# CBASS0_ISC register map
Vendor: Texas Instruments
Peripheral module from a debugger description file (folder am62x).
Registers are 32-bit, read-write, reset 0x0 unless marked. A register's access mark holds for its fields unless they carry their own. Offsets are as the file gives them; lines under a group give offsets from that group; [hi:lo] are bit positions; {n}, {i} and the like mark numbered series; 'fields as' and 'values as' point back to an identical list; <NAME> marks a mode.

## CBASS0_ISC
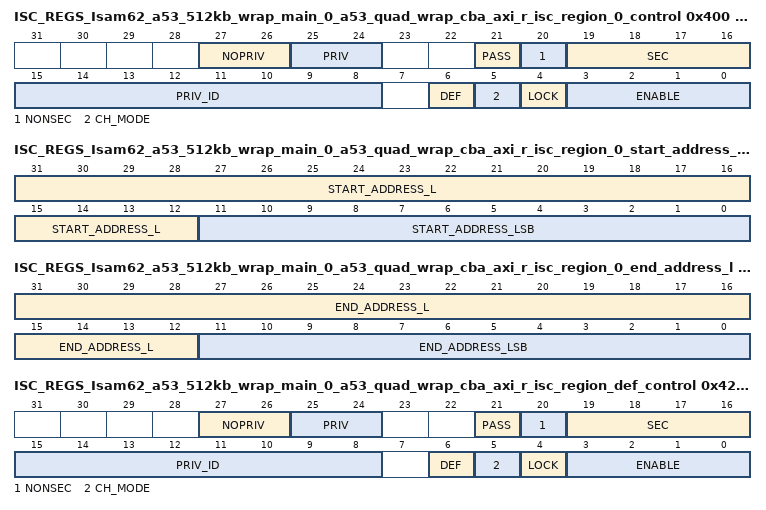
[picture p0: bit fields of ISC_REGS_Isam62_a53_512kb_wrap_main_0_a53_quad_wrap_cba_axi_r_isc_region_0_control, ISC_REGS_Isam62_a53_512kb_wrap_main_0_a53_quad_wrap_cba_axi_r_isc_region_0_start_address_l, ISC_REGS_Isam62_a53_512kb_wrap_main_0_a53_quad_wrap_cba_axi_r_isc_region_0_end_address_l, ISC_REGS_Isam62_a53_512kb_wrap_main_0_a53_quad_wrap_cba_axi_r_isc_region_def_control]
0x400 ISC_REGS_Isam62_a53_512kb_wrap_main_0_a53_quad_wrap_cba_axi_r_isc_region_0_control access not given reset 0x400 — The ISC Region 0 Control Register defines the control fields for the master Isam62_a53_512kb_wrap_main_0.a53_quad_wrap_cba_axi_r region 0 ISC.
  [27:26] NOPRIV rw — Clear output priv attribute. If each bit is set then the outgoing priv bit is cleared.
  [25:24] PRIV rw — Set outgoing priv attribute. If each bit is set then the outgoing priv bit is set.
  [21] PASS rw — No privID replacement, pass through value.
  [20] NONSEC rw — Make outgoing non-secure.
  [19:16] SEC rw — Make outgoing secure. A value of 0xA enables, others disable.
  [15:8] PRIV_ID rw
  [6] DEF ro — Default region indication. The default region is used when all other regions do not match.
  [5] CH_MODE rw — Enable channel mode to match region to a chanid value. Otherwise use address mode to match region to an address range.
  [4] LOCK — Lock region. Once set the region values cannot be modified. (access R/W1TS)
  [3:0] ENABLE rw — Enable region. A value of 0xA enables, others disable.
0x410 ISC_REGS_Isam62_a53_512kb_wrap_main_0_a53_quad_wrap_cba_axi_r_isc_region_0_start_address_l — The ISC Region 0 Start Address Low Register defines the start address bits 31 to 0 for the master Isam62_a53_512kb_wrap_main_0.a53_quad_wrap_cba_axi_r region 0 ISC.
  [31:12] START_ADDRESS_L — Start address bits 31 to 12.
  [11:0] START_ADDRESS_LSB — Start address bits 11 to 0 must be 0 as address must be 4KB aligned in address mode. Can also be channel number in channel mode.
0x414 ISC_REGS_Isam62_a53_512kb_wrap_main_0_a53_quad_wrap_cba_axi_r_isc_region_0_start_address_h — The ISC Region 0 Start Address High Register defines the start address bits 47 to 32 for the master Isam62_a53_512kb_wrap_main_0.a53_quad_wrap_cba_axi_r region 0 ISC.
  [15:0] START_ADDRESS_H — Start address bits 47 to 32.
0x418 ISC_REGS_Isam62_a53_512kb_wrap_main_0_a53_quad_wrap_cba_axi_r_isc_region_0_end_address_l access per field reset 0xFFF — The ISC Region 0 End Address Low Register defines the end included address bits 31 to 0 for the master Isam62_a53_512kb_wrap_main_0.a53_quad_wrap_cba_axi_r region 0 ISC.
  [31:12] END_ADDRESS_L rw — End address bits 31 to 12 to include in the match.
  [11:0] END_ADDRESS_LSB ro — End address bits 11 to 0 are forced to Fs as address must be 4KB aligned.
0x41C ISC_REGS_Isam62_a53_512kb_wrap_main_0_a53_quad_wrap_cba_axi_r_isc_region_0_end_address_h — The ISC Region 0 End Address High Register defines the end address bits 47 to 32 for the master Isam62_a53_512kb_wrap_main_0.a53_quad_wrap_cba_axi_r region 0 ISC.
  [15:0] END_ADDRESS_H — End address bits 47 to 32.
0x420 ISC_REGS_Isam62_a53_512kb_wrap_main_0_a53_quad_wrap_cba_axi_r_isc_region_def_control access not given reset 0x44A — The ISC Default Region Control Register defines the control fields for the master Isam62_a53_512kb_wrap_main_0.a53_quad_wrap_cba_axi_r region 1 ISC.
  [27:26] NOPRIV rw — Clear output priv attribute. If each bit is set then the outgoing priv bit is cleared, else the bit is unchanged. Do not set both priv and nopriv for the same bit.
  [25:24] PRIV rw — Set outgoing priv attribute. If each bit is set then the outgoing priv bit is set, else the bit is unchanged. Do not set both priv and nopriv for the same bit.
  [21] PASS rw — No privID replacement. A value of 1 will pass through privid value. A value of 0 will replace privid with priv_id field value.
  [20] NONSEC rw — Make outgoing non-secure. A value of 1 forces secure clear, others do nothing. Do not set both sec and nonsec.
  [19:16] SEC rw — Make outgoing secure. A value of 0xA forces secure set, others do nothing. Do not set both sec and nonsec.
  [15:8] PRIV_ID rw — Priv ID value to use if pass is 0.
  [6] DEF ro — Default region indication. The default region is used when all other regions do not match.
  [5] CH_MODE ro — Enable channel mode to match region to a chanid value. Otherwise use address mode to match region to an address range.
  [4] LOCK — Lock region. Once set, the region values cannot be modified. (access R/W1TS)
  [3:0] ENABLE ro — Enable region. A value of 0xA enables, others disable.
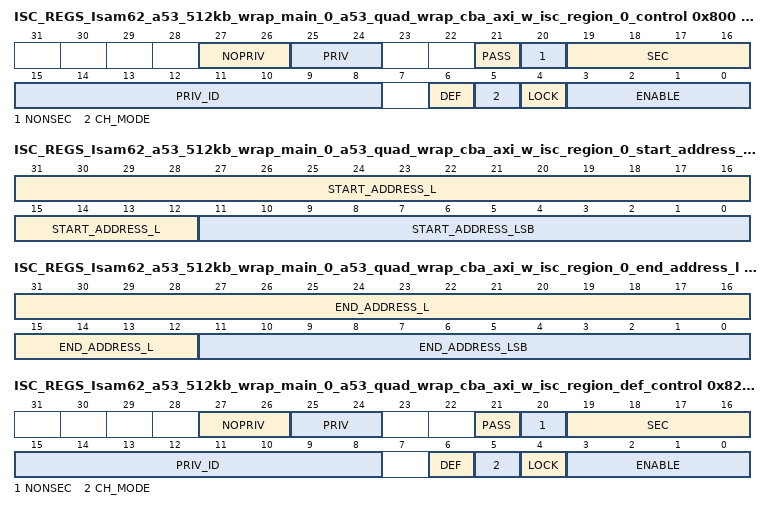
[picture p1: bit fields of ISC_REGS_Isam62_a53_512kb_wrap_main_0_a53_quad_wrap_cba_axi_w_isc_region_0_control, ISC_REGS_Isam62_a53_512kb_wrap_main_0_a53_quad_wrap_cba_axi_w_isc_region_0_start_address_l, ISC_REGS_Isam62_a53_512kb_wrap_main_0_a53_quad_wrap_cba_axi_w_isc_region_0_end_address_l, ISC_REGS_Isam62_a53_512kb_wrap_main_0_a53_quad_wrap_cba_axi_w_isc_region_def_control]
0x800 ISC_REGS_Isam62_a53_512kb_wrap_main_0_a53_quad_wrap_cba_axi_w_isc_region_0_control access not given reset 0x400 — The ISC Region 0 Control Register defines the control fields for the master Isam62_a53_512kb_wrap_main_0.a53_quad_wrap_cba_axi_w region 0 ISC.
  fields as ISC_REGS_Isam62_a53_512kb_wrap_main_0_a53_quad_wrap_cba_axi_r_isc_region_0_control
0x810 ISC_REGS_Isam62_a53_512kb_wrap_main_0_a53_quad_wrap_cba_axi_w_isc_region_0_start_address_l — The ISC Region 0 Start Address Low Register defines the start address bits 31 to 0 for the master Isam62_a53_512kb_wrap_main_0.a53_quad_wrap_cba_axi_w region 0 ISC.
  fields as ISC_REGS_Isam62_a53_512kb_wrap_main_0_a53_quad_wrap_cba_axi_r_isc_region_0_start_address_l
0x814 ISC_REGS_Isam62_a53_512kb_wrap_main_0_a53_quad_wrap_cba_axi_w_isc_region_0_start_address_h — The ISC Region 0 Start Address High Register defines the start address bits 47 to 32 for the master Isam62_a53_512kb_wrap_main_0.a53_quad_wrap_cba_axi_w region 0 ISC.
  [15:0] START_ADDRESS_H — Start address bits 47 to 32.
0x818 ISC_REGS_Isam62_a53_512kb_wrap_main_0_a53_quad_wrap_cba_axi_w_isc_region_0_end_address_l access per field reset 0xFFF — The ISC Region 0 End Address Low Register defines the end included address bits 31 to 0 for the master Isam62_a53_512kb_wrap_main_0.a53_quad_wrap_cba_axi_w region 0 ISC.
  fields as ISC_REGS_Isam62_a53_512kb_wrap_main_0_a53_quad_wrap_cba_axi_r_isc_region_0_end_address_l
0x81C ISC_REGS_Isam62_a53_512kb_wrap_main_0_a53_quad_wrap_cba_axi_w_isc_region_0_end_address_h — The ISC Region 0 End Address High Register defines the end address bits 47 to 32 for the master Isam62_a53_512kb_wrap_main_0.a53_quad_wrap_cba_axi_w region 0 ISC.
  [15:0] END_ADDRESS_H — End address bits 47 to 32.
0x820 ISC_REGS_Isam62_a53_512kb_wrap_main_0_a53_quad_wrap_cba_axi_w_isc_region_def_control access not given reset 0x44A — The ISC Default Region Control Register defines the control fields for the master Isam62_a53_512kb_wrap_main_0.a53_quad_wrap_cba_axi_w region 1 ISC.
  fields as ISC_REGS_Isam62_a53_512kb_wrap_main_0_a53_quad_wrap_cba_axi_r_isc_region_def_control
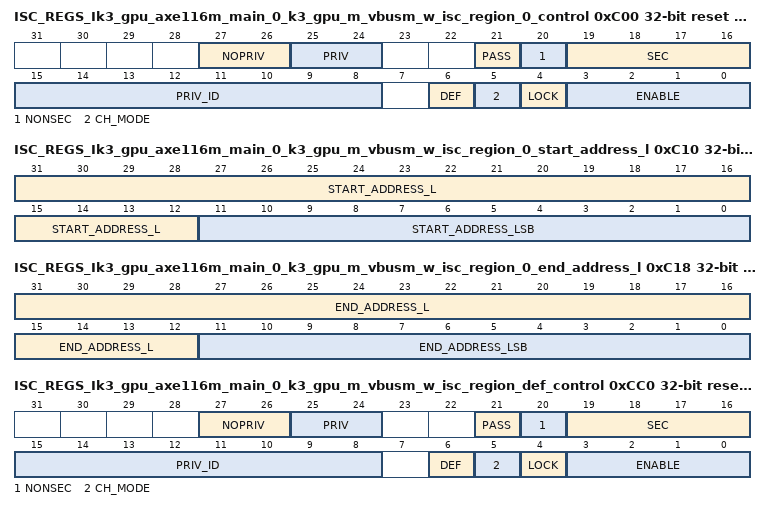
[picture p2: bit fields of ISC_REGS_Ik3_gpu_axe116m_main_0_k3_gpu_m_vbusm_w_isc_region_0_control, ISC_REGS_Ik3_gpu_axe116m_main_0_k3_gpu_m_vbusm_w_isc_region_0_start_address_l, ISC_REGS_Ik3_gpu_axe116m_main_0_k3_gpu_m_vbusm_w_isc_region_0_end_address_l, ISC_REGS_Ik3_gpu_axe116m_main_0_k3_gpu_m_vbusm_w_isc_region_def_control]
{0xC00+0x20*i} ISC_REGS_Ik3_gpu_axe116m_main_0_k3_gpu_m_vbusm_w_isc_region_{i}_control access not given reset 0xBB00 (i=0..5) — The ISC Region {i} Control Register defines the control fields for the master Ik3_gpu_axe116m_main_0.k3_gpu_m_vbusm_w region {i} ISC.
  fields as ISC_REGS_Isam62_a53_512kb_wrap_main_0_a53_quad_wrap_cba_axi_r_isc_region_0_control
{0xC10+0x20*i} ISC_REGS_Ik3_gpu_axe116m_main_0_k3_gpu_m_vbusm_w_isc_region_{i}_start_address_l (i=0..5) — The ISC Region {i} Start Address Low Register defines the start address bits 31 to 0 for the master Ik3_gpu_axe116m_main_0.k3_gpu_m_vbusm_w region {i} ISC.
  fields as ISC_REGS_Isam62_a53_512kb_wrap_main_0_a53_quad_wrap_cba_axi_r_isc_region_0_start_address_l
{0xC14+0x20*i} ISC_REGS_Ik3_gpu_axe116m_main_0_k3_gpu_m_vbusm_w_isc_region_{i}_start_address_h (i=0..5) — The ISC Region {i} Start Address High Register defines the start address bits 47 to 32 for the master Ik3_gpu_axe116m_main_0.k3_gpu_m_vbusm_w region {i} ISC.
  [15:0] START_ADDRESS_H — Start address bits 47 to 32.
{0xC18+0x20*i} ISC_REGS_Ik3_gpu_axe116m_main_0_k3_gpu_m_vbusm_w_isc_region_{i}_end_address_l access per field reset 0xFFF (i=0..5) — The ISC Region {i} End Address Low Register defines the end included address bits 31 to 0 for the master Ik3_gpu_axe116m_main_0.k3_gpu_m_vbusm_w region {i} ISC.
  fields as ISC_REGS_Isam62_a53_512kb_wrap_main_0_a53_quad_wrap_cba_axi_r_isc_region_0_end_address_l
{0xC1C+0x20*i} ISC_REGS_Ik3_gpu_axe116m_main_0_k3_gpu_m_vbusm_w_isc_region_{i}_end_address_h (i=0..5) — The ISC Region {i} End Address High Register defines the end address bits 47 to 32 for the master Ik3_gpu_axe116m_main_0.k3_gpu_m_vbusm_w region {i} ISC.
  [15:0] END_ADDRESS_H — End address bits 47 to 32.
0xCC0 ISC_REGS_Ik3_gpu_axe116m_main_0_k3_gpu_m_vbusm_w_isc_region_def_control access not given reset 0xBB4A — The ISC Default Region Control Register defines the control fields for the master Ik3_gpu_axe116m_main_0.k3_gpu_m_vbusm_w region 6 ISC.
  fields as ISC_REGS_Isam62_a53_512kb_wrap_main_0_a53_quad_wrap_cba_axi_r_isc_region_def_control
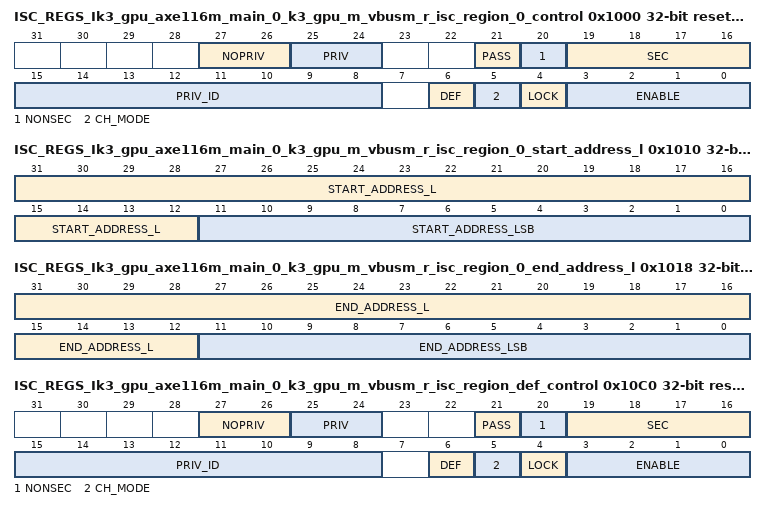
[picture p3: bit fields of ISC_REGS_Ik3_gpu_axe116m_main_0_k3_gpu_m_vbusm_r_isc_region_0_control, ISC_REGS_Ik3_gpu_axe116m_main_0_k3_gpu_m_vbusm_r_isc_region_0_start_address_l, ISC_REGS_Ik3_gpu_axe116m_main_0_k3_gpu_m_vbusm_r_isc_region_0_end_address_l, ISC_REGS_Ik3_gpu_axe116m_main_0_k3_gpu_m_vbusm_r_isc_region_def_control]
{0x1000+0x20*i} ISC_REGS_Ik3_gpu_axe116m_main_0_k3_gpu_m_vbusm_r_isc_region_{i}_control access not given reset 0xBB00 (i=0..5) — The ISC Region {i} Control Register defines the control fields for the master Ik3_gpu_axe116m_main_0.k3_gpu_m_vbusm_r region {i} ISC.
  fields as ISC_REGS_Isam62_a53_512kb_wrap_main_0_a53_quad_wrap_cba_axi_r_isc_region_0_control
{0x1010+0x20*i} ISC_REGS_Ik3_gpu_axe116m_main_0_k3_gpu_m_vbusm_r_isc_region_{i}_start_address_l (i=0..5) — The ISC Region {i} Start Address Low Register defines the start address bits 31 to 0 for the master Ik3_gpu_axe116m_main_0.k3_gpu_m_vbusm_r region {i} ISC.
  fields as ISC_REGS_Isam62_a53_512kb_wrap_main_0_a53_quad_wrap_cba_axi_r_isc_region_0_start_address_l
{0x1014+0x20*i} ISC_REGS_Ik3_gpu_axe116m_main_0_k3_gpu_m_vbusm_r_isc_region_{i}_start_address_h (i=0..5) — The ISC Region {i} Start Address High Register defines the start address bits 47 to 32 for the master Ik3_gpu_axe116m_main_0.k3_gpu_m_vbusm_r region {i} ISC.
  [15:0] START_ADDRESS_H — Start address bits 47 to 32.
{0x1018+0x20*i} ISC_REGS_Ik3_gpu_axe116m_main_0_k3_gpu_m_vbusm_r_isc_region_{i}_end_address_l access per field reset 0xFFF (i=0..5) — The ISC Region {i} End Address Low Register defines the end included address bits 31 to 0 for the master Ik3_gpu_axe116m_main_0.k3_gpu_m_vbusm_r region {i} ISC.
  fields as ISC_REGS_Isam62_a53_512kb_wrap_main_0_a53_quad_wrap_cba_axi_r_isc_region_0_end_address_l
{0x101C+0x20*i} ISC_REGS_Ik3_gpu_axe116m_main_0_k3_gpu_m_vbusm_r_isc_region_{i}_end_address_h (i=0..5) — The ISC Region {i} End Address High Register defines the end address bits 47 to 32 for the master Ik3_gpu_axe116m_main_0.k3_gpu_m_vbusm_r region {i} ISC.
  [15:0] END_ADDRESS_H — End address bits 47 to 32.
0x10C0 ISC_REGS_Ik3_gpu_axe116m_main_0_k3_gpu_m_vbusm_r_isc_region_def_control access not given reset 0xBB4A — The ISC Default Region Control Register defines the control fields for the master Ik3_gpu_axe116m_main_0.k3_gpu_m_vbusm_r region 6 ISC.
  fields as ISC_REGS_Isam62_a53_512kb_wrap_main_0_a53_quad_wrap_cba_axi_r_isc_region_def_control
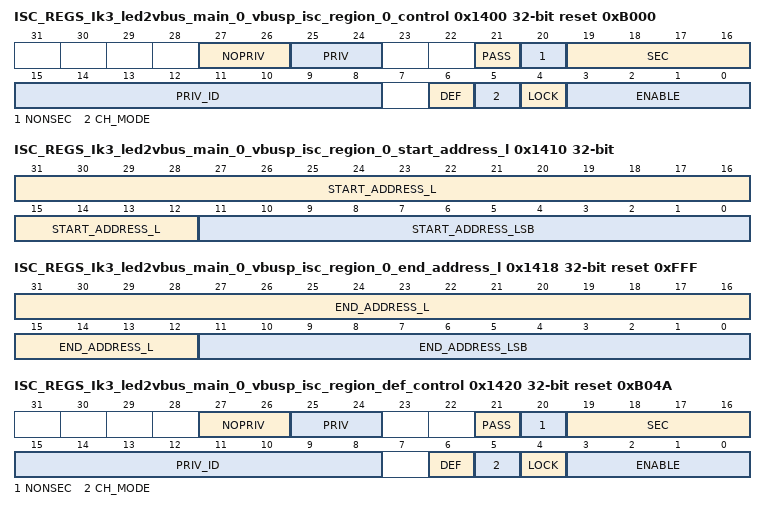
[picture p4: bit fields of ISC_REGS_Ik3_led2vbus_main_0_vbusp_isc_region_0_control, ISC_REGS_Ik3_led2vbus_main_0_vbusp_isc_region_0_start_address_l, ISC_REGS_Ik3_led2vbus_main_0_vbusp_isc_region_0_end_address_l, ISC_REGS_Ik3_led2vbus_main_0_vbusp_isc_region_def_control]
0x1400 ISC_REGS_Ik3_led2vbus_main_0_vbusp_isc_region_0_control access not given reset 0xB000 — The ISC Region 0 Control Register defines the control fields for the master Ik3_led2vbus_main_0.vbusp region 0 ISC.
  fields as ISC_REGS_Isam62_a53_512kb_wrap_main_0_a53_quad_wrap_cba_axi_r_isc_region_0_control
0x1410 ISC_REGS_Ik3_led2vbus_main_0_vbusp_isc_region_0_start_address_l — The ISC Region 0 Start Address Low Register defines the start address bits 31 to 0 for the master Ik3_led2vbus_main_0.vbusp region 0 ISC.
  fields as ISC_REGS_Isam62_a53_512kb_wrap_main_0_a53_quad_wrap_cba_axi_r_isc_region_0_start_address_l
0x1414 ISC_REGS_Ik3_led2vbus_main_0_vbusp_isc_region_0_start_address_h — The ISC Region 0 Start Address High Register defines the start address bits 47 to 32 for the master Ik3_led2vbus_main_0.vbusp region 0 ISC.
  [15:0] START_ADDRESS_H — Start address bits 47 to 32.
0x1418 ISC_REGS_Ik3_led2vbus_main_0_vbusp_isc_region_0_end_address_l access per field reset 0xFFF — The ISC Region 0 End Address Low Register defines the end included address bits 31 to 0 for the master Ik3_led2vbus_main_0.vbusp region 0 ISC.
  fields as ISC_REGS_Isam62_a53_512kb_wrap_main_0_a53_quad_wrap_cba_axi_r_isc_region_0_end_address_l
0x141C ISC_REGS_Ik3_led2vbus_main_0_vbusp_isc_region_0_end_address_h — The ISC Region 0 End Address High Register defines the end address bits 47 to 32 for the master Ik3_led2vbus_main_0.vbusp region 0 ISC.
  [15:0] END_ADDRESS_H — End address bits 47 to 32.
0x1420 ISC_REGS_Ik3_led2vbus_main_0_vbusp_isc_region_def_control access not given reset 0xB04A — The ISC Default Region Control Register defines the control fields for the master Ik3_led2vbus_main_0.vbusp region 1 ISC.
  fields as ISC_REGS_Isam62_a53_512kb_wrap_main_0_a53_quad_wrap_cba_axi_r_isc_region_def_control
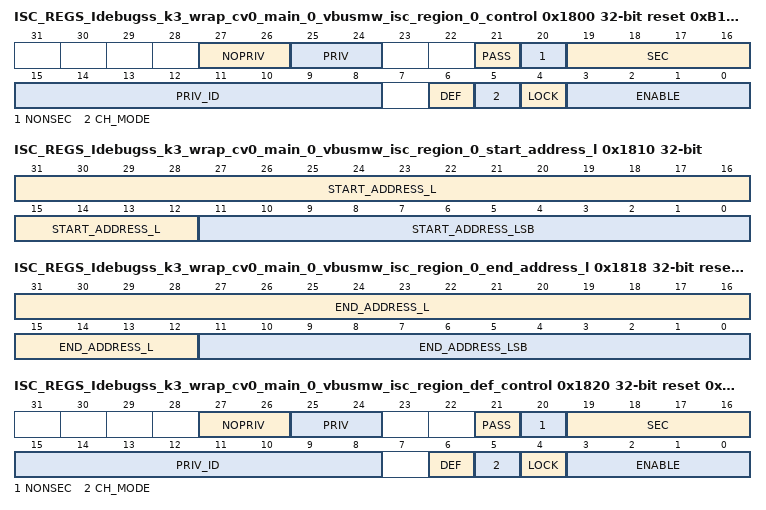
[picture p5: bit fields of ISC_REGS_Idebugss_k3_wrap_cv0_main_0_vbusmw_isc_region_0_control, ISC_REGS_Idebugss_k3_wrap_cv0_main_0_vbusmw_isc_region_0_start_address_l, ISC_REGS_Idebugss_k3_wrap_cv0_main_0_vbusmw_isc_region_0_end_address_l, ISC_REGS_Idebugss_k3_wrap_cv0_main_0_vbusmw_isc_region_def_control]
0x1800 ISC_REGS_Idebugss_k3_wrap_cv0_main_0_vbusmw_isc_region_0_control access not given reset 0xB100 — The ISC Region 0 Control Register defines the control fields for the master Idebugss_k3_wrap_cv0_main_0.vbusmw region 0 ISC.
  fields as ISC_REGS_Isam62_a53_512kb_wrap_main_0_a53_quad_wrap_cba_axi_r_isc_region_0_control
0x1810 ISC_REGS_Idebugss_k3_wrap_cv0_main_0_vbusmw_isc_region_0_start_address_l — The ISC Region 0 Start Address Low Register defines the start address bits 31 to 0 for the master Idebugss_k3_wrap_cv0_main_0.vbusmw region 0 ISC.
  fields as ISC_REGS_Isam62_a53_512kb_wrap_main_0_a53_quad_wrap_cba_axi_r_isc_region_0_start_address_l
0x1814 ISC_REGS_Idebugss_k3_wrap_cv0_main_0_vbusmw_isc_region_0_start_address_h — The ISC Region 0 Start Address High Register defines the start address bits 47 to 32 for the master Idebugss_k3_wrap_cv0_main_0.vbusmw region 0 ISC.
  [15:0] START_ADDRESS_H — Start address bits 47 to 32.
0x1818 ISC_REGS_Idebugss_k3_wrap_cv0_main_0_vbusmw_isc_region_0_end_address_l access per field reset 0xFFF — The ISC Region 0 End Address Low Register defines the end included address bits 31 to 0 for the master Idebugss_k3_wrap_cv0_main_0.vbusmw region 0 ISC.
  fields as ISC_REGS_Isam62_a53_512kb_wrap_main_0_a53_quad_wrap_cba_axi_r_isc_region_0_end_address_l
0x181C ISC_REGS_Idebugss_k3_wrap_cv0_main_0_vbusmw_isc_region_0_end_address_h — The ISC Region 0 End Address High Register defines the end address bits 47 to 32 for the master Idebugss_k3_wrap_cv0_main_0.vbusmw region 0 ISC.
  [15:0] END_ADDRESS_H — End address bits 47 to 32.
0x1820 ISC_REGS_Idebugss_k3_wrap_cv0_main_0_vbusmw_isc_region_def_control access not given reset 0xB14A — The ISC Default Region Control Register defines the control fields for the master Idebugss_k3_wrap_cv0_main_0.vbusmw region 1 ISC.
  fields as ISC_REGS_Isam62_a53_512kb_wrap_main_0_a53_quad_wrap_cba_axi_r_isc_region_def_control
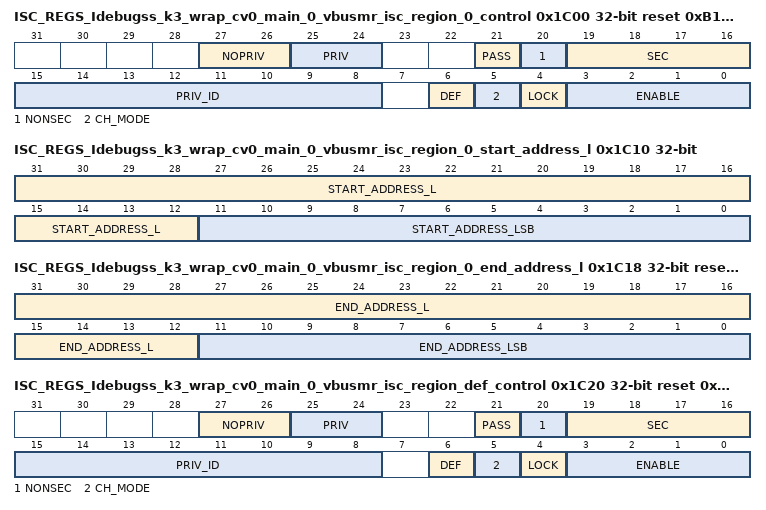
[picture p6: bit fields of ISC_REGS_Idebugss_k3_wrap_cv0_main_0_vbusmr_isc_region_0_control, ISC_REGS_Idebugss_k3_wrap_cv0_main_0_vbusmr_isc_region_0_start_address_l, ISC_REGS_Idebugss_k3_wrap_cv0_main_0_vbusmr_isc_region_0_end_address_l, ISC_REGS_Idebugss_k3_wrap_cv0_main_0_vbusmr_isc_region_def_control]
0x1C00 ISC_REGS_Idebugss_k3_wrap_cv0_main_0_vbusmr_isc_region_0_control access not given reset 0xB100 — The ISC Region 0 Control Register defines the control fields for the master Idebugss_k3_wrap_cv0_main_0.vbusmr region 0 ISC.
  fields as ISC_REGS_Isam62_a53_512kb_wrap_main_0_a53_quad_wrap_cba_axi_r_isc_region_0_control
0x1C10 ISC_REGS_Idebugss_k3_wrap_cv0_main_0_vbusmr_isc_region_0_start_address_l — The ISC Region 0 Start Address Low Register defines the start address bits 31 to 0 for the master Idebugss_k3_wrap_cv0_main_0.vbusmr region 0 ISC.
  fields as ISC_REGS_Isam62_a53_512kb_wrap_main_0_a53_quad_wrap_cba_axi_r_isc_region_0_start_address_l
0x1C14 ISC_REGS_Idebugss_k3_wrap_cv0_main_0_vbusmr_isc_region_0_start_address_h — The ISC Region 0 Start Address High Register defines the start address bits 47 to 32 for the master Idebugss_k3_wrap_cv0_main_0.vbusmr region 0 ISC.
  [15:0] START_ADDRESS_H — Start address bits 47 to 32.
0x1C18 ISC_REGS_Idebugss_k3_wrap_cv0_main_0_vbusmr_isc_region_0_end_address_l access per field reset 0xFFF — The ISC Region 0 End Address Low Register defines the end included address bits 31 to 0 for the master Idebugss_k3_wrap_cv0_main_0.vbusmr region 0 ISC.
  fields as ISC_REGS_Isam62_a53_512kb_wrap_main_0_a53_quad_wrap_cba_axi_r_isc_region_0_end_address_l
0x1C1C ISC_REGS_Idebugss_k3_wrap_cv0_main_0_vbusmr_isc_region_0_end_address_h — The ISC Region 0 End Address High Register defines the end address bits 47 to 32 for the master Idebugss_k3_wrap_cv0_main_0.vbusmr region 0 ISC.
  [15:0] END_ADDRESS_H — End address bits 47 to 32.
0x1C20 ISC_REGS_Idebugss_k3_wrap_cv0_main_0_vbusmr_isc_region_def_control access not given reset 0xB14A — The ISC Default Region Control Register defines the control fields for the master Idebugss_k3_wrap_cv0_main_0.vbusmr region 1 ISC.
  fields as ISC_REGS_Isam62_a53_512kb_wrap_main_0_a53_quad_wrap_cba_axi_r_isc_region_def_control
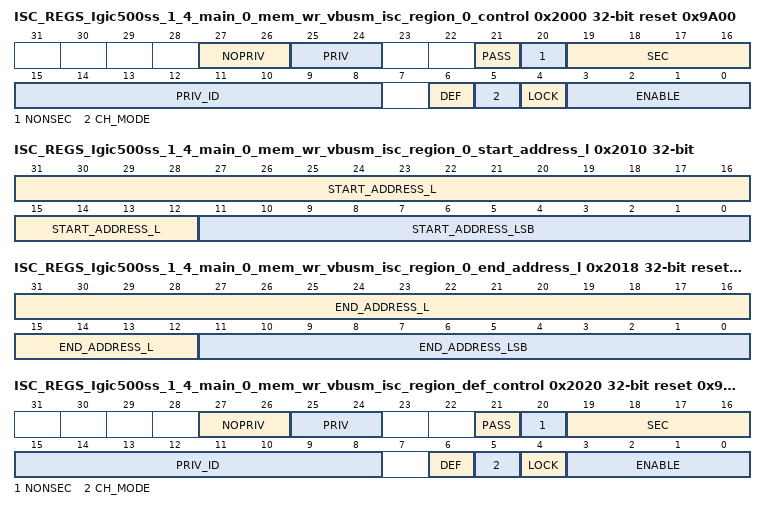
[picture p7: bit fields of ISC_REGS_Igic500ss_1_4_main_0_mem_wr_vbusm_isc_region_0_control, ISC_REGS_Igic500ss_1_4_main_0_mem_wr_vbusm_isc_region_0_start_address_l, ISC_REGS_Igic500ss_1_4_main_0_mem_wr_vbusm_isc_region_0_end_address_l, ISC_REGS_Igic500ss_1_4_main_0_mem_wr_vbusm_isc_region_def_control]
0x2000 ISC_REGS_Igic500ss_1_4_main_0_mem_wr_vbusm_isc_region_0_control access not given reset 0x9A00 — The ISC Region 0 Control Register defines the control fields for the master Igic500ss_1_4_main_0.mem_wr_vbusm region 0 ISC.
  fields as ISC_REGS_Isam62_a53_512kb_wrap_main_0_a53_quad_wrap_cba_axi_r_isc_region_0_control
0x2010 ISC_REGS_Igic500ss_1_4_main_0_mem_wr_vbusm_isc_region_0_start_address_l — The ISC Region 0 Start Address Low Register defines the start address bits 31 to 0 for the master Igic500ss_1_4_main_0.mem_wr_vbusm region 0 ISC.
  fields as ISC_REGS_Isam62_a53_512kb_wrap_main_0_a53_quad_wrap_cba_axi_r_isc_region_0_start_address_l
0x2014 ISC_REGS_Igic500ss_1_4_main_0_mem_wr_vbusm_isc_region_0_start_address_h — The ISC Region 0 Start Address High Register defines the start address bits 47 to 32 for the master Igic500ss_1_4_main_0.mem_wr_vbusm region 0 ISC.
  [15:0] START_ADDRESS_H — Start address bits 47 to 32.
0x2018 ISC_REGS_Igic500ss_1_4_main_0_mem_wr_vbusm_isc_region_0_end_address_l access per field reset 0xFFF — The ISC Region 0 End Address Low Register defines the end included address bits 31 to 0 for the master Igic500ss_1_4_main_0.mem_wr_vbusm region 0 ISC.
  fields as ISC_REGS_Isam62_a53_512kb_wrap_main_0_a53_quad_wrap_cba_axi_r_isc_region_0_end_address_l
0x201C ISC_REGS_Igic500ss_1_4_main_0_mem_wr_vbusm_isc_region_0_end_address_h — The ISC Region 0 End Address High Register defines the end address bits 47 to 32 for the master Igic500ss_1_4_main_0.mem_wr_vbusm region 0 ISC.
  [15:0] END_ADDRESS_H — End address bits 47 to 32.
0x2020 ISC_REGS_Igic500ss_1_4_main_0_mem_wr_vbusm_isc_region_def_control access not given reset 0x9A4A — The ISC Default Region Control Register defines the control fields for the master Igic500ss_1_4_main_0.mem_wr_vbusm region 1 ISC.
  fields as ISC_REGS_Isam62_a53_512kb_wrap_main_0_a53_quad_wrap_cba_axi_r_isc_region_def_control
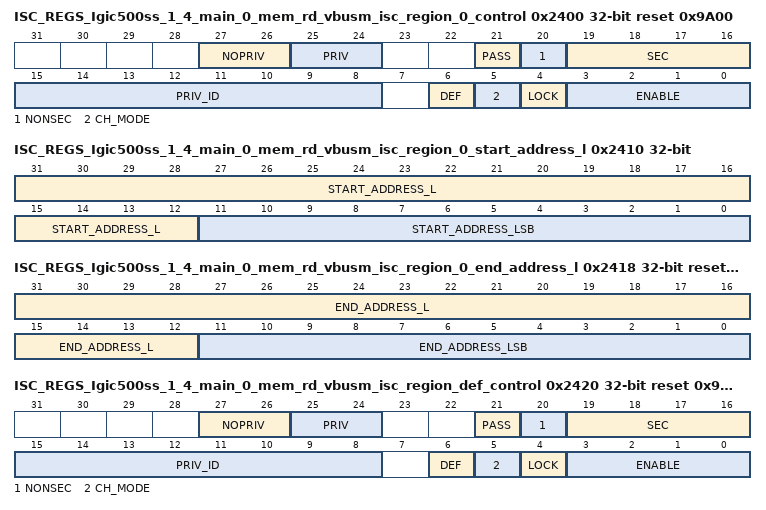
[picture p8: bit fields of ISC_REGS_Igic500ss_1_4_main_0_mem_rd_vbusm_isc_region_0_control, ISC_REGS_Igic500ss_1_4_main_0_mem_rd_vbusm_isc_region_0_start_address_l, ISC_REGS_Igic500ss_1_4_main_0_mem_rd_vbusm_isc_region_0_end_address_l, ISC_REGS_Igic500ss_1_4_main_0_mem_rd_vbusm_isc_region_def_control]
0x2400 ISC_REGS_Igic500ss_1_4_main_0_mem_rd_vbusm_isc_region_0_control access not given reset 0x9A00 — The ISC Region 0 Control Register defines the control fields for the master Igic500ss_1_4_main_0.mem_rd_vbusm region 0 ISC.
  fields as ISC_REGS_Isam62_a53_512kb_wrap_main_0_a53_quad_wrap_cba_axi_r_isc_region_0_control
0x2410 ISC_REGS_Igic500ss_1_4_main_0_mem_rd_vbusm_isc_region_0_start_address_l — The ISC Region 0 Start Address Low Register defines the start address bits 31 to 0 for the master Igic500ss_1_4_main_0.mem_rd_vbusm region 0 ISC.
  fields as ISC_REGS_Isam62_a53_512kb_wrap_main_0_a53_quad_wrap_cba_axi_r_isc_region_0_start_address_l
0x2414 ISC_REGS_Igic500ss_1_4_main_0_mem_rd_vbusm_isc_region_0_start_address_h — The ISC Region 0 Start Address High Register defines the start address bits 47 to 32 for the master Igic500ss_1_4_main_0.mem_rd_vbusm region 0 ISC.
  [15:0] START_ADDRESS_H — Start address bits 47 to 32.
0x2418 ISC_REGS_Igic500ss_1_4_main_0_mem_rd_vbusm_isc_region_0_end_address_l access per field reset 0xFFF — The ISC Region 0 End Address Low Register defines the end included address bits 31 to 0 for the master Igic500ss_1_4_main_0.mem_rd_vbusm region 0 ISC.
  fields as ISC_REGS_Isam62_a53_512kb_wrap_main_0_a53_quad_wrap_cba_axi_r_isc_region_0_end_address_l
0x241C ISC_REGS_Igic500ss_1_4_main_0_mem_rd_vbusm_isc_region_0_end_address_h — The ISC Region 0 End Address High Register defines the end address bits 47 to 32 for the master Igic500ss_1_4_main_0.mem_rd_vbusm region 0 ISC.
  [15:0] END_ADDRESS_H — End address bits 47 to 32.
0x2420 ISC_REGS_Igic500ss_1_4_main_0_mem_rd_vbusm_isc_region_def_control access not given reset 0x9A4A — The ISC Default Region Control Register defines the control fields for the master Igic500ss_1_4_main_0.mem_rd_vbusm region 1 ISC.
  fields as ISC_REGS_Isam62_a53_512kb_wrap_main_0_a53_quad_wrap_cba_axi_r_isc_region_def_control
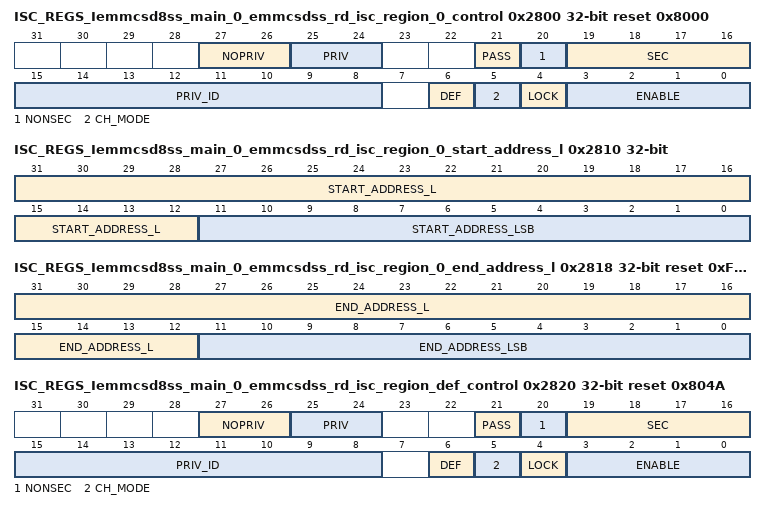
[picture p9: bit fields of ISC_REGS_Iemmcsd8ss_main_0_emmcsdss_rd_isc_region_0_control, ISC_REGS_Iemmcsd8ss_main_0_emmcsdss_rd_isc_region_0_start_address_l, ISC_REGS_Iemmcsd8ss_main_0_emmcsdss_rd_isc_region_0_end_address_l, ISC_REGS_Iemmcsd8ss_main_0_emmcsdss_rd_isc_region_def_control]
0x2800 ISC_REGS_Iemmcsd8ss_main_0_emmcsdss_rd_isc_region_0_control access not given reset 0x8000 — The ISC Region 0 Control Register defines the control fields for the master Iemmcsd8ss_main_0.emmcsdss_rd region 0 ISC.
  fields as ISC_REGS_Isam62_a53_512kb_wrap_main_0_a53_quad_wrap_cba_axi_r_isc_region_0_control
0x2810 ISC_REGS_Iemmcsd8ss_main_0_emmcsdss_rd_isc_region_0_start_address_l — The ISC Region 0 Start Address Low Register defines the start address bits 31 to 0 for the master Iemmcsd8ss_main_0.emmcsdss_rd region 0 ISC.
  fields as ISC_REGS_Isam62_a53_512kb_wrap_main_0_a53_quad_wrap_cba_axi_r_isc_region_0_start_address_l
0x2814 ISC_REGS_Iemmcsd8ss_main_0_emmcsdss_rd_isc_region_0_start_address_h — The ISC Region 0 Start Address High Register defines the start address bits 47 to 32 for the master Iemmcsd8ss_main_0.emmcsdss_rd region 0 ISC.
  [15:0] START_ADDRESS_H — Start address bits 47 to 32.
0x2818 ISC_REGS_Iemmcsd8ss_main_0_emmcsdss_rd_isc_region_0_end_address_l access per field reset 0xFFF — The ISC Region 0 End Address Low Register defines the end included address bits 31 to 0 for the master Iemmcsd8ss_main_0.emmcsdss_rd region 0 ISC.
  fields as ISC_REGS_Isam62_a53_512kb_wrap_main_0_a53_quad_wrap_cba_axi_r_isc_region_0_end_address_l
0x281C ISC_REGS_Iemmcsd8ss_main_0_emmcsdss_rd_isc_region_0_end_address_h — The ISC Region 0 End Address High Register defines the end address bits 47 to 32 for the master Iemmcsd8ss_main_0.emmcsdss_rd region 0 ISC.
  [15:0] END_ADDRESS_H — End address bits 47 to 32.
0x2820 ISC_REGS_Iemmcsd8ss_main_0_emmcsdss_rd_isc_region_def_control access not given reset 0x804A — The ISC Default Region Control Register defines the control fields for the master Iemmcsd8ss_main_0.emmcsdss_rd region 1 ISC.
  fields as ISC_REGS_Isam62_a53_512kb_wrap_main_0_a53_quad_wrap_cba_axi_r_isc_region_def_control
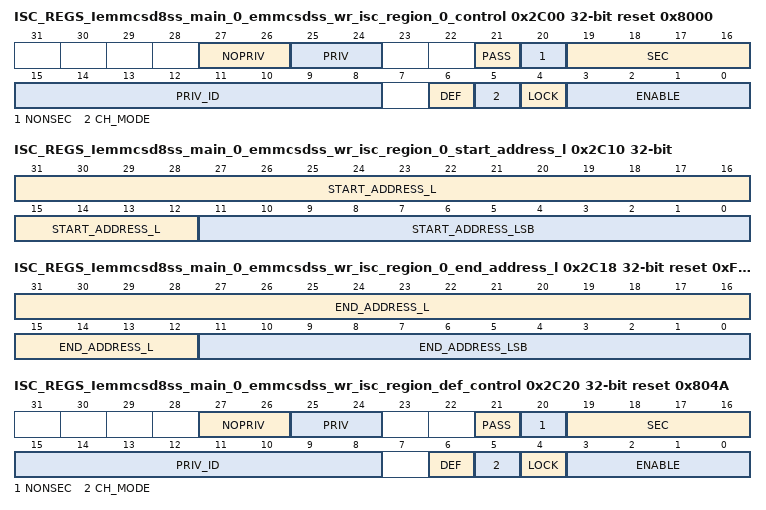
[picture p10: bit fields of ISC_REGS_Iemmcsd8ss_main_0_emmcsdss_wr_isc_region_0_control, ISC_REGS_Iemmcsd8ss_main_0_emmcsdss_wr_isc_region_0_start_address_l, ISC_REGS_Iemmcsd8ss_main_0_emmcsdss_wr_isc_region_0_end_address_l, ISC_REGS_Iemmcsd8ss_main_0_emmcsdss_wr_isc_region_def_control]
0x2C00 ISC_REGS_Iemmcsd8ss_main_0_emmcsdss_wr_isc_region_0_control access not given reset 0x8000 — The ISC Region 0 Control Register defines the control fields for the master Iemmcsd8ss_main_0.emmcsdss_wr region 0 ISC.
  fields as ISC_REGS_Isam62_a53_512kb_wrap_main_0_a53_quad_wrap_cba_axi_r_isc_region_0_control
0x2C10 ISC_REGS_Iemmcsd8ss_main_0_emmcsdss_wr_isc_region_0_start_address_l — The ISC Region 0 Start Address Low Register defines the start address bits 31 to 0 for the master Iemmcsd8ss_main_0.emmcsdss_wr region 0 ISC.
  fields as ISC_REGS_Isam62_a53_512kb_wrap_main_0_a53_quad_wrap_cba_axi_r_isc_region_0_start_address_l
0x2C14 ISC_REGS_Iemmcsd8ss_main_0_emmcsdss_wr_isc_region_0_start_address_h — The ISC Region 0 Start Address High Register defines the start address bits 47 to 32 for the master Iemmcsd8ss_main_0.emmcsdss_wr region 0 ISC.
  [15:0] START_ADDRESS_H — Start address bits 47 to 32.
0x2C18 ISC_REGS_Iemmcsd8ss_main_0_emmcsdss_wr_isc_region_0_end_address_l access per field reset 0xFFF — The ISC Region 0 End Address Low Register defines the end included address bits 31 to 0 for the master Iemmcsd8ss_main_0.emmcsdss_wr region 0 ISC.
  fields as ISC_REGS_Isam62_a53_512kb_wrap_main_0_a53_quad_wrap_cba_axi_r_isc_region_0_end_address_l
0x2C1C ISC_REGS_Iemmcsd8ss_main_0_emmcsdss_wr_isc_region_0_end_address_h — The ISC Region 0 End Address High Register defines the end address bits 47 to 32 for the master Iemmcsd8ss_main_0.emmcsdss_wr region 0 ISC.
  [15:0] END_ADDRESS_H — End address bits 47 to 32.
0x2C20 ISC_REGS_Iemmcsd8ss_main_0_emmcsdss_wr_isc_region_def_control access not given reset 0x804A — The ISC Default Region Control Register defines the control fields for the master Iemmcsd8ss_main_0.emmcsdss_wr region 1 ISC.
  fields as ISC_REGS_Isam62_a53_512kb_wrap_main_0_a53_quad_wrap_cba_axi_r_isc_region_def_control
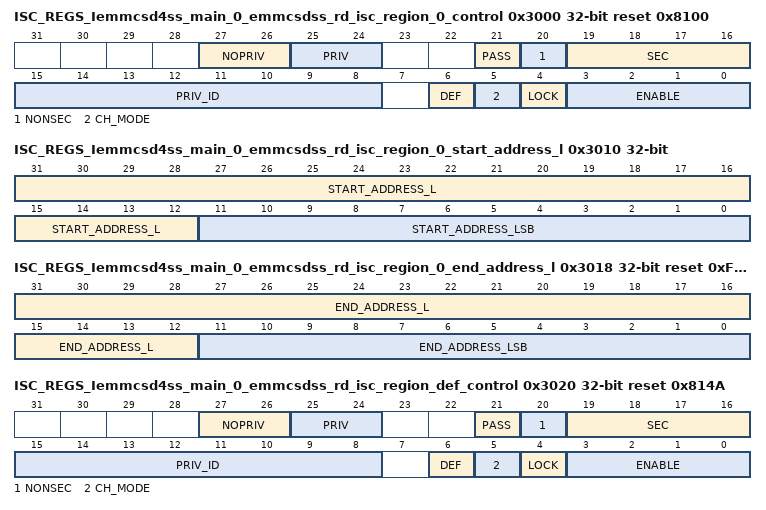
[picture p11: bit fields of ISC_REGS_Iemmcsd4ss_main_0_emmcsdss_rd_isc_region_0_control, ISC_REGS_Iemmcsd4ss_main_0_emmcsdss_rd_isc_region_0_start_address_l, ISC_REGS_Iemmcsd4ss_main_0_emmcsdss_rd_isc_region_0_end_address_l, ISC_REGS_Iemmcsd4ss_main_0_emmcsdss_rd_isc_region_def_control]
0x3000 ISC_REGS_Iemmcsd4ss_main_0_emmcsdss_rd_isc_region_0_control access not given reset 0x8100 — The ISC Region 0 Control Register defines the control fields for the master Iemmcsd4ss_main_0.emmcsdss_rd region 0 ISC.
  fields as ISC_REGS_Isam62_a53_512kb_wrap_main_0_a53_quad_wrap_cba_axi_r_isc_region_0_control
0x3010 ISC_REGS_Iemmcsd4ss_main_0_emmcsdss_rd_isc_region_0_start_address_l — The ISC Region 0 Start Address Low Register defines the start address bits 31 to 0 for the master Iemmcsd4ss_main_0.emmcsdss_rd region 0 ISC.
  fields as ISC_REGS_Isam62_a53_512kb_wrap_main_0_a53_quad_wrap_cba_axi_r_isc_region_0_start_address_l
0x3014 ISC_REGS_Iemmcsd4ss_main_0_emmcsdss_rd_isc_region_0_start_address_h — The ISC Region 0 Start Address High Register defines the start address bits 47 to 32 for the master Iemmcsd4ss_main_0.emmcsdss_rd region 0 ISC.
  [15:0] START_ADDRESS_H — Start address bits 47 to 32.
0x3018 ISC_REGS_Iemmcsd4ss_main_0_emmcsdss_rd_isc_region_0_end_address_l access per field reset 0xFFF — The ISC Region 0 End Address Low Register defines the end included address bits 31 to 0 for the master Iemmcsd4ss_main_0.emmcsdss_rd region 0 ISC.
  fields as ISC_REGS_Isam62_a53_512kb_wrap_main_0_a53_quad_wrap_cba_axi_r_isc_region_0_end_address_l
0x301C ISC_REGS_Iemmcsd4ss_main_0_emmcsdss_rd_isc_region_0_end_address_h — The ISC Region 0 End Address High Register defines the end address bits 47 to 32 for the master Iemmcsd4ss_main_0.emmcsdss_rd region 0 ISC.
  [15:0] END_ADDRESS_H — End address bits 47 to 32.
0x3020 ISC_REGS_Iemmcsd4ss_main_0_emmcsdss_rd_isc_region_def_control access not given reset 0x814A — The ISC Default Region Control Register defines the control fields for the master Iemmcsd4ss_main_0.emmcsdss_rd region 1 ISC.
  fields as ISC_REGS_Isam62_a53_512kb_wrap_main_0_a53_quad_wrap_cba_axi_r_isc_region_def_control
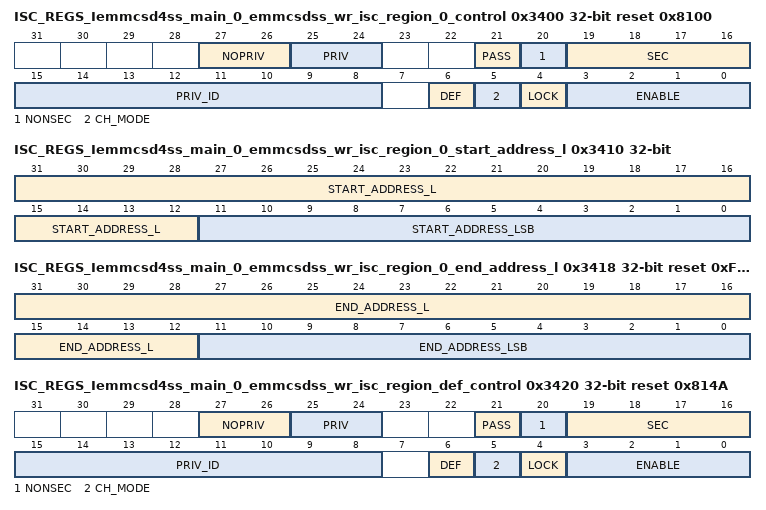
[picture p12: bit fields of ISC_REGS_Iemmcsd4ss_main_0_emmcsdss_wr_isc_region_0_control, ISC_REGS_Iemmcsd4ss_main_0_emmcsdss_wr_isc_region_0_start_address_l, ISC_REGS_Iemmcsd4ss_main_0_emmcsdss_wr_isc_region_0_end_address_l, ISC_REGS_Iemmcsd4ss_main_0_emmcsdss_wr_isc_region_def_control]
0x3400 ISC_REGS_Iemmcsd4ss_main_0_emmcsdss_wr_isc_region_0_control access not given reset 0x8100 — The ISC Region 0 Control Register defines the control fields for the master Iemmcsd4ss_main_0.emmcsdss_wr region 0 ISC.
  fields as ISC_REGS_Isam62_a53_512kb_wrap_main_0_a53_quad_wrap_cba_axi_r_isc_region_0_control
0x3410 ISC_REGS_Iemmcsd4ss_main_0_emmcsdss_wr_isc_region_0_start_address_l — The ISC Region 0 Start Address Low Register defines the start address bits 31 to 0 for the master Iemmcsd4ss_main_0.emmcsdss_wr region 0 ISC.
  fields as ISC_REGS_Isam62_a53_512kb_wrap_main_0_a53_quad_wrap_cba_axi_r_isc_region_0_start_address_l
0x3414 ISC_REGS_Iemmcsd4ss_main_0_emmcsdss_wr_isc_region_0_start_address_h — The ISC Region 0 Start Address High Register defines the start address bits 47 to 32 for the master Iemmcsd4ss_main_0.emmcsdss_wr region 0 ISC.
  [15:0] START_ADDRESS_H — Start address bits 47 to 32.
0x3418 ISC_REGS_Iemmcsd4ss_main_0_emmcsdss_wr_isc_region_0_end_address_l access per field reset 0xFFF — The ISC Region 0 End Address Low Register defines the end included address bits 31 to 0 for the master Iemmcsd4ss_main_0.emmcsdss_wr region 0 ISC.
  fields as ISC_REGS_Isam62_a53_512kb_wrap_main_0_a53_quad_wrap_cba_axi_r_isc_region_0_end_address_l
0x341C ISC_REGS_Iemmcsd4ss_main_0_emmcsdss_wr_isc_region_0_end_address_h — The ISC Region 0 End Address High Register defines the end address bits 47 to 32 for the master Iemmcsd4ss_main_0.emmcsdss_wr region 0 ISC.
  [15:0] END_ADDRESS_H — End address bits 47 to 32.
0x3420 ISC_REGS_Iemmcsd4ss_main_0_emmcsdss_wr_isc_region_def_control access not given reset 0x814A — The ISC Default Region Control Register defines the control fields for the master Iemmcsd4ss_main_0.emmcsdss_wr region 1 ISC.
  fields as ISC_REGS_Isam62_a53_512kb_wrap_main_0_a53_quad_wrap_cba_axi_r_isc_region_def_control
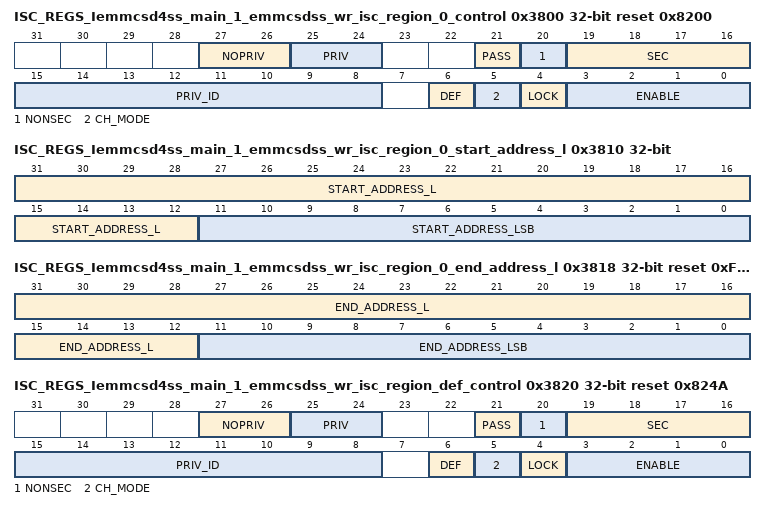
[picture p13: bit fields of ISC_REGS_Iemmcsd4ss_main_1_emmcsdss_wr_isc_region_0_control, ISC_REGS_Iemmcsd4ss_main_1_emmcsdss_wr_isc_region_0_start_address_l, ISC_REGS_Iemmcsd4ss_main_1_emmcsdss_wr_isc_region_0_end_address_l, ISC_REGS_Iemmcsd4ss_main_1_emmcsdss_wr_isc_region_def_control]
0x3800 ISC_REGS_Iemmcsd4ss_main_1_emmcsdss_wr_isc_region_0_control access not given reset 0x8200 — The ISC Region 0 Control Register defines the control fields for the master Iemmcsd4ss_main_1.emmcsdss_wr region 0 ISC.
  fields as ISC_REGS_Isam62_a53_512kb_wrap_main_0_a53_quad_wrap_cba_axi_r_isc_region_0_control
0x3810 ISC_REGS_Iemmcsd4ss_main_1_emmcsdss_wr_isc_region_0_start_address_l — The ISC Region 0 Start Address Low Register defines the start address bits 31 to 0 for the master Iemmcsd4ss_main_1.emmcsdss_wr region 0 ISC.
  fields as ISC_REGS_Isam62_a53_512kb_wrap_main_0_a53_quad_wrap_cba_axi_r_isc_region_0_start_address_l
0x3814 ISC_REGS_Iemmcsd4ss_main_1_emmcsdss_wr_isc_region_0_start_address_h — The ISC Region 0 Start Address High Register defines the start address bits 47 to 32 for the master Iemmcsd4ss_main_1.emmcsdss_wr region 0 ISC.
  [15:0] START_ADDRESS_H — Start address bits 47 to 32.
0x3818 ISC_REGS_Iemmcsd4ss_main_1_emmcsdss_wr_isc_region_0_end_address_l access per field reset 0xFFF — The ISC Region 0 End Address Low Register defines the end included address bits 31 to 0 for the master Iemmcsd4ss_main_1.emmcsdss_wr region 0 ISC.
  fields as ISC_REGS_Isam62_a53_512kb_wrap_main_0_a53_quad_wrap_cba_axi_r_isc_region_0_end_address_l
0x381C ISC_REGS_Iemmcsd4ss_main_1_emmcsdss_wr_isc_region_0_end_address_h — The ISC Region 0 End Address High Register defines the end address bits 47 to 32 for the master Iemmcsd4ss_main_1.emmcsdss_wr region 0 ISC.
  [15:0] END_ADDRESS_H — End address bits 47 to 32.
0x3820 ISC_REGS_Iemmcsd4ss_main_1_emmcsdss_wr_isc_region_def_control access not given reset 0x824A — The ISC Default Region Control Register defines the control fields for the master Iemmcsd4ss_main_1.emmcsdss_wr region 1 ISC.
  fields as ISC_REGS_Isam62_a53_512kb_wrap_main_0_a53_quad_wrap_cba_axi_r_isc_region_def_control
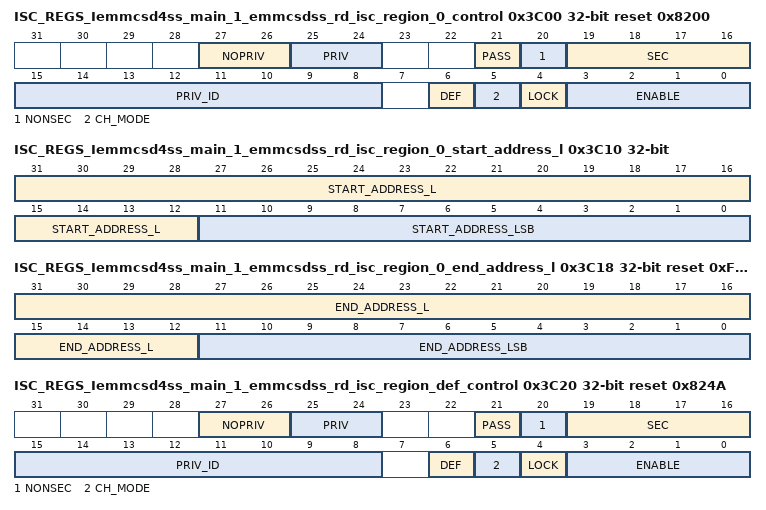
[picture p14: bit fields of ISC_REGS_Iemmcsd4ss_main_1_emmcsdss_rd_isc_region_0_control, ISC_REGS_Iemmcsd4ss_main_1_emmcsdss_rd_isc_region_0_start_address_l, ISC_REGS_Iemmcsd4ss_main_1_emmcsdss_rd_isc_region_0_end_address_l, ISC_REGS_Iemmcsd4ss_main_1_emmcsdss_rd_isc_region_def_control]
0x3C00 ISC_REGS_Iemmcsd4ss_main_1_emmcsdss_rd_isc_region_0_control access not given reset 0x8200 — The ISC Region 0 Control Register defines the control fields for the master Iemmcsd4ss_main_1.emmcsdss_rd region 0 ISC.
  fields as ISC_REGS_Isam62_a53_512kb_wrap_main_0_a53_quad_wrap_cba_axi_r_isc_region_0_control
0x3C10 ISC_REGS_Iemmcsd4ss_main_1_emmcsdss_rd_isc_region_0_start_address_l — The ISC Region 0 Start Address Low Register defines the start address bits 31 to 0 for the master Iemmcsd4ss_main_1.emmcsdss_rd region 0 ISC.
  fields as ISC_REGS_Isam62_a53_512kb_wrap_main_0_a53_quad_wrap_cba_axi_r_isc_region_0_start_address_l
0x3C14 ISC_REGS_Iemmcsd4ss_main_1_emmcsdss_rd_isc_region_0_start_address_h — The ISC Region 0 Start Address High Register defines the start address bits 47 to 32 for the master Iemmcsd4ss_main_1.emmcsdss_rd region 0 ISC.
  [15:0] START_ADDRESS_H — Start address bits 47 to 32.
0x3C18 ISC_REGS_Iemmcsd4ss_main_1_emmcsdss_rd_isc_region_0_end_address_l access per field reset 0xFFF — The ISC Region 0 End Address Low Register defines the end included address bits 31 to 0 for the master Iemmcsd4ss_main_1.emmcsdss_rd region 0 ISC.
  fields as ISC_REGS_Isam62_a53_512kb_wrap_main_0_a53_quad_wrap_cba_axi_r_isc_region_0_end_address_l
0x3C1C ISC_REGS_Iemmcsd4ss_main_1_emmcsdss_rd_isc_region_0_end_address_h — The ISC Region 0 End Address High Register defines the end address bits 47 to 32 for the master Iemmcsd4ss_main_1.emmcsdss_rd region 0 ISC.
  [15:0] END_ADDRESS_H — End address bits 47 to 32.
0x3C20 ISC_REGS_Iemmcsd4ss_main_1_emmcsdss_rd_isc_region_def_control access not given reset 0x824A — The ISC Default Region Control Register defines the control fields for the master Iemmcsd4ss_main_1.emmcsdss_rd region 1 ISC.
  fields as ISC_REGS_Isam62_a53_512kb_wrap_main_0_a53_quad_wrap_cba_axi_r_isc_region_def_control
0x4000 ISC_REGS_Iusb2ss_16ffc_main_0_mstw0_isc_region_0_control access not given reset 0x9B00 — The ISC Region 0 Control Register defines the control fields for the master Iusb2ss_16ffc_main_0.mstw0 region 0 ISC.
  fields as ISC_REGS_Isam62_a53_512kb_wrap_main_0_a53_quad_wrap_cba_axi_r_isc_region_0_control
0x4010 ISC_REGS_Iusb2ss_16ffc_main_0_mstw0_isc_region_0_start_address_l — The ISC Region 0 Start Address Low Register defines the start address bits 31 to 0 for the master Iusb2ss_16ffc_main_0.mstw0 region 0 ISC.
  fields as ISC_REGS_Isam62_a53_512kb_wrap_main_0_a53_quad_wrap_cba_axi_r_isc_region_0_start_address_l
0x4014 ISC_REGS_Iusb2ss_16ffc_main_0_mstw0_isc_region_0_start_address_h — The ISC Region 0 Start Address High Register defines the start address bits 47 to 32 for the master Iusb2ss_16ffc_main_0.mstw0 region 0 ISC.
  [15:0] START_ADDRESS_H — Start address bits 47 to 32.
0x4018 ISC_REGS_Iusb2ss_16ffc_main_0_mstw0_isc_region_0_end_address_l access per field reset 0xFFF — The ISC Region 0 End Address Low Register defines the end included address bits 31 to 0 for the master Iusb2ss_16ffc_main_0.mstw0 region 0 ISC.
  fields as ISC_REGS_Isam62_a53_512kb_wrap_main_0_a53_quad_wrap_cba_axi_r_isc_region_0_end_address_l
0x401C ISC_REGS_Iusb2ss_16ffc_main_0_mstw0_isc_region_0_end_address_h — The ISC Region 0 End Address High Register defines the end address bits 47 to 32 for the master Iusb2ss_16ffc_main_0.mstw0 region 0 ISC.
  [15:0] END_ADDRESS_H — End address bits 47 to 32.
0x4020 ISC_REGS_Iusb2ss_16ffc_main_0_mstw0_isc_region_def_control access not given reset 0x9B4A — The ISC Default Region Control Register defines the control fields for the master Iusb2ss_16ffc_main_0.mstw0 region 1 ISC.
  fields as ISC_REGS_Isam62_a53_512kb_wrap_main_0_a53_quad_wrap_cba_axi_r_isc_region_def_control
0x4400 ISC_REGS_Iusb2ss_16ffc_main_0_mstr0_isc_region_0_control access not given reset 0x9B00 — The ISC Region 0 Control Register defines the control fields for the master Iusb2ss_16ffc_main_0.mstr0 region 0 ISC.
  fields as ISC_REGS_Isam62_a53_512kb_wrap_main_0_a53_quad_wrap_cba_axi_r_isc_region_0_control
0x4410 ISC_REGS_Iusb2ss_16ffc_main_0_mstr0_isc_region_0_start_address_l — The ISC Region 0 Start Address Low Register defines the start address bits 31 to 0 for the master Iusb2ss_16ffc_main_0.mstr0 region 0 ISC.
  fields as ISC_REGS_Isam62_a53_512kb_wrap_main_0_a53_quad_wrap_cba_axi_r_isc_region_0_start_address_l
0x4414 ISC_REGS_Iusb2ss_16ffc_main_0_mstr0_isc_region_0_start_address_h — The ISC Region 0 Start Address High Register defines the start address bits 47 to 32 for the master Iusb2ss_16ffc_main_0.mstr0 region 0 ISC.
  [15:0] START_ADDRESS_H — Start address bits 47 to 32.
0x4418 ISC_REGS_Iusb2ss_16ffc_main_0_mstr0_isc_region_0_end_address_l access per field reset 0xFFF — The ISC Region 0 End Address Low Register defines the end included address bits 31 to 0 for the master Iusb2ss_16ffc_main_0.mstr0 region 0 ISC.
  fields as ISC_REGS_Isam62_a53_512kb_wrap_main_0_a53_quad_wrap_cba_axi_r_isc_region_0_end_address_l
0x441C ISC_REGS_Iusb2ss_16ffc_main_0_mstr0_isc_region_0_end_address_h — The ISC Region 0 End Address High Register defines the end address bits 47 to 32 for the master Iusb2ss_16ffc_main_0.mstr0 region 0 ISC.
  [15:0] END_ADDRESS_H — End address bits 47 to 32.
0x4420 ISC_REGS_Iusb2ss_16ffc_main_0_mstr0_isc_region_def_control access not given reset 0x9B4A — The ISC Default Region Control Register defines the control fields for the master Iusb2ss_16ffc_main_0.mstr0 region 1 ISC.
  fields as ISC_REGS_Isam62_a53_512kb_wrap_main_0_a53_quad_wrap_cba_axi_r_isc_region_def_control
0x4800 ISC_REGS_Iusb2ss_16ffc_main_1_mstr0_isc_region_0_control access not given reset 0x9C00 — The ISC Region 0 Control Register defines the control fields for the master Iusb2ss_16ffc_main_1.mstr0 region 0 ISC.
  fields as ISC_REGS_Isam62_a53_512kb_wrap_main_0_a53_quad_wrap_cba_axi_r_isc_region_0_control
0x4810 ISC_REGS_Iusb2ss_16ffc_main_1_mstr0_isc_region_0_start_address_l — The ISC Region 0 Start Address Low Register defines the start address bits 31 to 0 for the master Iusb2ss_16ffc_main_1.mstr0 region 0 ISC.
  fields as ISC_REGS_Isam62_a53_512kb_wrap_main_0_a53_quad_wrap_cba_axi_r_isc_region_0_start_address_l
0x4814 ISC_REGS_Iusb2ss_16ffc_main_1_mstr0_isc_region_0_start_address_h — The ISC Region 0 Start Address High Register defines the start address bits 47 to 32 for the master Iusb2ss_16ffc_main_1.mstr0 region 0 ISC.
  [15:0] START_ADDRESS_H — Start address bits 47 to 32.
0x4818 ISC_REGS_Iusb2ss_16ffc_main_1_mstr0_isc_region_0_end_address_l access per field reset 0xFFF — The ISC Region 0 End Address Low Register defines the end included address bits 31 to 0 for the master Iusb2ss_16ffc_main_1.mstr0 region 0 ISC.
  fields as ISC_REGS_Isam62_a53_512kb_wrap_main_0_a53_quad_wrap_cba_axi_r_isc_region_0_end_address_l
0x481C ISC_REGS_Iusb2ss_16ffc_main_1_mstr0_isc_region_0_end_address_h — The ISC Region 0 End Address High Register defines the end address bits 47 to 32 for the master Iusb2ss_16ffc_main_1.mstr0 region 0 ISC.
  [15:0] END_ADDRESS_H — End address bits 47 to 32.
0x4820 ISC_REGS_Iusb2ss_16ffc_main_1_mstr0_isc_region_def_control access not given reset 0x9C4A — The ISC Default Region Control Register defines the control fields for the master Iusb2ss_16ffc_main_1.mstr0 region 1 ISC.
  fields as ISC_REGS_Isam62_a53_512kb_wrap_main_0_a53_quad_wrap_cba_axi_r_isc_region_def_control
0x4C00 ISC_REGS_Iusb2ss_16ffc_main_1_mstw0_isc_region_0_control access not given reset 0x9C00 — The ISC Region 0 Control Register defines the control fields for the master Iusb2ss_16ffc_main_1.mstw0 region 0 ISC.
  fields as ISC_REGS_Isam62_a53_512kb_wrap_main_0_a53_quad_wrap_cba_axi_r_isc_region_0_control
0x4C10 ISC_REGS_Iusb2ss_16ffc_main_1_mstw0_isc_region_0_start_address_l — The ISC Region 0 Start Address Low Register defines the start address bits 31 to 0 for the master Iusb2ss_16ffc_main_1.mstw0 region 0 ISC.
  fields as ISC_REGS_Isam62_a53_512kb_wrap_main_0_a53_quad_wrap_cba_axi_r_isc_region_0_start_address_l
0x4C14 ISC_REGS_Iusb2ss_16ffc_main_1_mstw0_isc_region_0_start_address_h — The ISC Region 0 Start Address High Register defines the start address bits 47 to 32 for the master Iusb2ss_16ffc_main_1.mstw0 region 0 ISC.
  [15:0] START_ADDRESS_H — Start address bits 47 to 32.
0x4C18 ISC_REGS_Iusb2ss_16ffc_main_1_mstw0_isc_region_0_end_address_l access per field reset 0xFFF — The ISC Region 0 End Address Low Register defines the end included address bits 31 to 0 for the master Iusb2ss_16ffc_main_1.mstw0 region 0 ISC.
  fields as ISC_REGS_Isam62_a53_512kb_wrap_main_0_a53_quad_wrap_cba_axi_r_isc_region_0_end_address_l
0x4C1C ISC_REGS_Iusb2ss_16ffc_main_1_mstw0_isc_region_0_end_address_h — The ISC Region 0 End Address High Register defines the end address bits 47 to 32 for the master Iusb2ss_16ffc_main_1.mstw0 region 0 ISC.
  [15:0] END_ADDRESS_H — End address bits 47 to 32.
0x4C20 ISC_REGS_Iusb2ss_16ffc_main_1_mstw0_isc_region_def_control access not given reset 0x9C4A — The ISC Default Region Control Register defines the control fields for the master Iusb2ss_16ffc_main_1.mstw0 region 1 ISC.
  fields as ISC_REGS_Isam62_a53_512kb_wrap_main_0_a53_quad_wrap_cba_axi_r_isc_region_def_control
{0x5000+0x20*i} ISC_REGS_Ik3_dss_ul_main_0_vbusm_dma_isc_region_{i}_control access not given reset 0xAD00 (i=0..3) — The ISC Region {i} Control Register defines the control fields for the master Ik3_dss_ul_main_0.vbusm_dma region {i} ISC.
  fields as ISC_REGS_Isam62_a53_512kb_wrap_main_0_a53_quad_wrap_cba_axi_r_isc_region_0_control
{0x5010+0x20*i} ISC_REGS_Ik3_dss_ul_main_0_vbusm_dma_isc_region_{i}_start_address_l (i=0..3) — The ISC Region {i} Start Address Low Register defines the start address bits 31 to 0 for the master Ik3_dss_ul_main_0.vbusm_dma region {i} ISC.
  fields as ISC_REGS_Isam62_a53_512kb_wrap_main_0_a53_quad_wrap_cba_axi_r_isc_region_0_start_address_l
{0x5014+0x20*i} ISC_REGS_Ik3_dss_ul_main_0_vbusm_dma_isc_region_{i}_start_address_h (i=0..3) — The ISC Region {i} Start Address High Register defines the start address bits 47 to 32 for the master Ik3_dss_ul_main_0.vbusm_dma region {i} ISC.
  [15:0] START_ADDRESS_H — Start address bits 47 to 32.
{0x5018+0x20*i} ISC_REGS_Ik3_dss_ul_main_0_vbusm_dma_isc_region_{i}_end_address_l access per field reset 0xFFF (i=0..3) — The ISC Region {i} End Address Low Register defines the end included address bits 31 to 0 for the master Ik3_dss_ul_main_0.vbusm_dma region {i} ISC.
  fields as ISC_REGS_Isam62_a53_512kb_wrap_main_0_a53_quad_wrap_cba_axi_r_isc_region_0_end_address_l
{0x501C+0x20*i} ISC_REGS_Ik3_dss_ul_main_0_vbusm_dma_isc_region_{i}_end_address_h (i=0..3) — The ISC Region {i} End Address High Register defines the end address bits 47 to 32 for the master Ik3_dss_ul_main_0.vbusm_dma region {i} ISC.
  [15:0] END_ADDRESS_H — End address bits 47 to 32.
0x5080 ISC_REGS_Ik3_dss_ul_main_0_vbusm_dma_isc_region_def_control access not given reset 0xAD4A — The ISC Default Region Control Register defines the control fields for the master Ik3_dss_ul_main_0.vbusm_dma region 4 ISC.
  fields as ISC_REGS_Isam62_a53_512kb_wrap_main_0_a53_quad_wrap_cba_axi_r_isc_region_def_control
0x5400 ISC_REGS_Isa3ss_am62_main_0_ctxcach_ext_dma_isc_region_0_control access not given reset 0x9800 — The ISC Region 0 Control Register defines the control fields for the master Isa3ss_am62_main_0.ctxcach_ext_dma region 0 ISC.
  fields as ISC_REGS_Isam62_a53_512kb_wrap_main_0_a53_quad_wrap_cba_axi_r_isc_region_0_control
0x5410 ISC_REGS_Isa3ss_am62_main_0_ctxcach_ext_dma_isc_region_0_start_address_l — The ISC Region 0 Start Address Low Register defines the start address bits 31 to 0 for the master Isa3ss_am62_main_0.ctxcach_ext_dma region 0 ISC.
  fields as ISC_REGS_Isam62_a53_512kb_wrap_main_0_a53_quad_wrap_cba_axi_r_isc_region_0_start_address_l
0x5414 ISC_REGS_Isa3ss_am62_main_0_ctxcach_ext_dma_isc_region_0_start_address_h — The ISC Region 0 Start Address High Register defines the start address bits 47 to 32 for the master Isa3ss_am62_main_0.ctxcach_ext_dma region 0 ISC.
  [15:0] START_ADDRESS_H — Start address bits 47 to 32.
0x5418 ISC_REGS_Isa3ss_am62_main_0_ctxcach_ext_dma_isc_region_0_end_address_l access per field reset 0xFFF — The ISC Region 0 End Address Low Register defines the end included address bits 31 to 0 for the master Isa3ss_am62_main_0.ctxcach_ext_dma region 0 ISC.
  fields as ISC_REGS_Isam62_a53_512kb_wrap_main_0_a53_quad_wrap_cba_axi_r_isc_region_0_end_address_l
0x541C ISC_REGS_Isa3ss_am62_main_0_ctxcach_ext_dma_isc_region_0_end_address_h — The ISC Region 0 End Address High Register defines the end address bits 47 to 32 for the master Isa3ss_am62_main_0.ctxcach_ext_dma region 0 ISC.
  [15:0] END_ADDRESS_H — End address bits 47 to 32.
0x5420 ISC_REGS_Isa3ss_am62_main_0_ctxcach_ext_dma_isc_region_def_control access not given reset 0x984A — The ISC Default Region Control Register defines the control fields for the master Isa3ss_am62_main_0.ctxcach_ext_dma region 1 ISC.
  fields as ISC_REGS_Isam62_a53_512kb_wrap_main_0_a53_quad_wrap_cba_axi_r_isc_region_def_control
